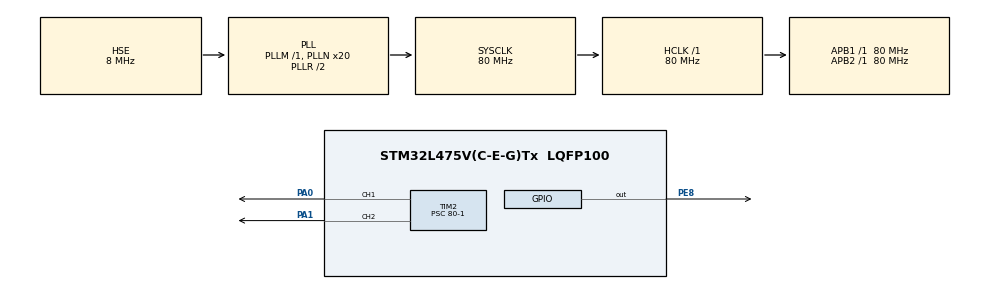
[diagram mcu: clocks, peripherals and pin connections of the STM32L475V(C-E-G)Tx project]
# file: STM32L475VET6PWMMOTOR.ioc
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Mcu.Family=STM32L4
Mcu.Name=STM32L475V(C-E-G)Tx
Mcu.Package=LQFP100
NVIC.PriorityGroup=NVIC_PRIORITYGROUP_4
PA0.Signal=S_TIM2_CH1
PA1.Signal=S_TIM2_CH2
PC14-OSC32_IN\ (PC14).Mode=LSE-External-Oscillator
PC14-OSC32_IN\ (PC14).Signal=RCC_OSC32_IN
PC15-OSC32_OUT\ (PC15).Mode=LSE-External-Oscillator
PC15-OSC32_OUT\ (PC15).Signal=RCC_OSC32_OUT
PE8.GPIO_ModeDefaultOutputPP=GPIO_MODE_OUTPUT_PP
PE8.GPIO_PuPd=GPIO_PULLUP
PE8.GPIO_Speed=GPIO_SPEED_FREQ_HIGH
PE8.PinState=GPIO_PIN_SET
PE8.Signal=GPIO_Output
PH0-OSC_IN\ (PH0).Mode=HSE-External-Oscillator
PH0-OSC_IN\ (PH0).Signal=RCC_OSC_IN
PH1-OSC_OUT\ (PH1).Mode=HSE-External-Oscillator
PH1-OSC_OUT\ (PH1).Signal=RCC_OSC_OUT
ProjectManager.HeapSize=0x200
ProjectManager.StackSize=0x400
ProjectManager.TargetToolchain=MDK-ARM V5.32
RCC.ADCFreq_Value=32000000
RCC.AHBFreq_Value=80000000
RCC.APB1Freq_Value=80000000
RCC.APB1TimFreq_Value=80000000
RCC.APB2Freq_Value=80000000
RCC.APB2TimFreq_Value=80000000
RCC.CortexFreq_Value=80000000
RCC.HCLKFreq_Value=80000000
RCC.HSE_VALUE=8000000
RCC.HSI_VALUE=16000000
RCC.MSI_VALUE=4000000
RCC.PLLN=20
RCC.PLLSourceVirtual=RCC_PLLSOURCE_HSE
RCC.SYSCLKFreq_VALUE=80000000
RCC.SYSCLKSource=RCC_SYSCLKSOURCE_PLLCLK
RCC.USBFreq_Value=32000000
RCC.VCOOutputFreq_Value=160000000
SH.S_TIM2_CH1.0=TIM2_CH1,PWM Generation1 CH1
SH.S_TIM2_CH2.0=TIM2_CH2,PWM Generation2 CH2
TIM2.Channel-PWM\ Generation1\ CH1=TIM_CHANNEL_1
TIM2.Channel-PWM\ Generation2\ CH2=TIM_CHANNEL_2
TIM2.Period=1000-1
TIM2.Prescaler=80-1
VP_TIM2_VS_ClockSourceINT.Mode=Internal
board=custom

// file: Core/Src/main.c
/* USER CODE BEGIN Header */
/**
  ******************************************************************************
  * @file           : main.c
  * @brief          : Main program body
  ******************************************************************************
  * @attention
  *
  * Copyright (c) 2023 STMicroelectronics.
  * All rights reserved.
  *
  * This software is licensed under terms that can be found in the LICENSE file
  * in the root directory of this software component.
  * If no LICENSE file comes with this software, it is provided AS-IS.
  *
  ******************************************************************************
  */
/* USER CODE END Header */
#include "main.h"
#include "tim.h"
#include "gpio.h"

/* USER CODE BEGIN PV */
int16_t pwmvalue=200;	//pwm波的占空比，最低200 最高1000
int16_t dir=1;		//1. 正转 0. 反转
int16_t speed=1; 	//1. 加速 0. 减速
int16_t time=0;

/* USER CODE END PV */

void SystemClock_Config(void);

int main(void)
{

  /* MCU Configuration--------------------------------------------------------*/

  /* Reset of all peripherals, Initializes the Flash interface and the Systick. */
  HAL_Init();

  /* Configure the system clock */
  SystemClock_Config();

  /* Initialize all configured peripherals */
  MX_GPIO_Init();
  MX_TIM2_Init();
  /* USER CODE BEGIN 2 */
  HAL_TIM_PWM_Start(&htim2,TIM_CHANNEL_1);
  HAL_TIM_PWM_Start(&htim2,TIM_CHANNEL_2);

  /* USER CODE END 2 */

  /* Infinite loop */
  /* USER CODE BEGIN WHILE */
  while (1)
  {
	  if(speed) pwmvalue += 5;
	  else pwmvalue -= 5;

	  if(pwmvalue>=1000) speed=0;
	  if(pwmvalue<=100)
	  {
		  speed=1;

		  dir=dir^0x01;
	  }

	  if(dir)
	  {
		  htim2.Instance->CCR1=pwmvalue; //寄存器写法
		  htim2.Instance->CCR2=0;

//		  __HAL_TIM_SetCompare(&htim2,TIM_CHANNEL_1,pwmvalue); //宏定义写法
//		  __HAL_TIM_SetCompare(&htim2,TIM_CHANNEL_2,0);
	  }
	  else
	  {
		  htim2.Instance->CCR1=0;//寄存器写法
		  htim2.Instance->CCR2=pwmvalue;

//		  __HAL_TIM_SetCompare(&htim2,TIM_CHANNEL_1,0);//宏定义写法
//		  __HAL_TIM_SetCompare(&htim2,TIM_CHANNEL_2,pwmvalue);
	  }

	  time++;

	  if(time>20)
	  {
		  time=0;
		  HAL_GPIO_TogglePin(GPIOE, GPIO_PIN_8);
	  }

	  HAL_Delay(50);

    /* USER CODE END WHILE */

  }
}

void SystemClock_Config(void)
{
  RCC_OscInitTypeDef RCC_OscInitStruct = {0};
  RCC_ClkInitTypeDef RCC_ClkInitStruct = {0};

  /** Configure the main internal regulator output voltage
  */
  if (HAL_PWREx_ControlVoltageScaling(PWR_REGULATOR_VOLTAGE_SCALE1) != HAL_OK)
  {
    Error_Handler();
  }

  /** Initializes the RCC Oscillators according to the specified parameters
  * in the RCC_OscInitTypeDef structure.
  */
  RCC_OscInitStruct.OscillatorType = RCC_OSCILLATORTYPE_HSE;
  RCC_OscInitStruct.HSEState = RCC_HSE_ON;
  RCC_OscInitStruct.PLL.PLLState = RCC_PLL_ON;
  RCC_OscInitStruct.PLL.PLLSource = RCC_PLLSOURCE_HSE;
  RCC_OscInitStruct.PLL.PLLM = 1;
  RCC_OscInitStruct.PLL.PLLN = 20;
  RCC_OscInitStruct.PLL.PLLP = RCC_PLLP_DIV7;
  RCC_OscInitStruct.PLL.PLLQ = RCC_PLLQ_DIV2;
  RCC_OscInitStruct.PLL.PLLR = RCC_PLLR_DIV2;
  if (HAL_RCC_OscConfig(&RCC_OscInitStruct) != HAL_OK)
  {
    Error_Handler();
  }

  /** Initializes the CPU, AHB and APB buses clocks
  */
  RCC_ClkInitStruct.ClockType = RCC_CLOCKTYPE_HCLK|RCC_CLOCKTYPE_SYSCLK
                              |RCC_CLOCKTYPE_PCLK1|RCC_CLOCKTYPE_PCLK2;
  RCC_ClkInitStruct.SYSCLKSource = RCC_SYSCLKSOURCE_PLLCLK;
  RCC_ClkInitStruct.AHBCLKDivider = RCC_SYSCLK_DIV1;
  RCC_ClkInitStruct.APB1CLKDivider = RCC_HCLK_DIV1;
  RCC_ClkInitStruct.APB2CLKDivider = RCC_HCLK_DIV1;

  if (HAL_RCC_ClockConfig(&RCC_ClkInitStruct, FLASH_LATENCY_4) != HAL_OK)
  {
    Error_Handler();
  }
}

void Error_Handler(void)
{
  __disable_irq();
  while (1)
  {
  }
}
